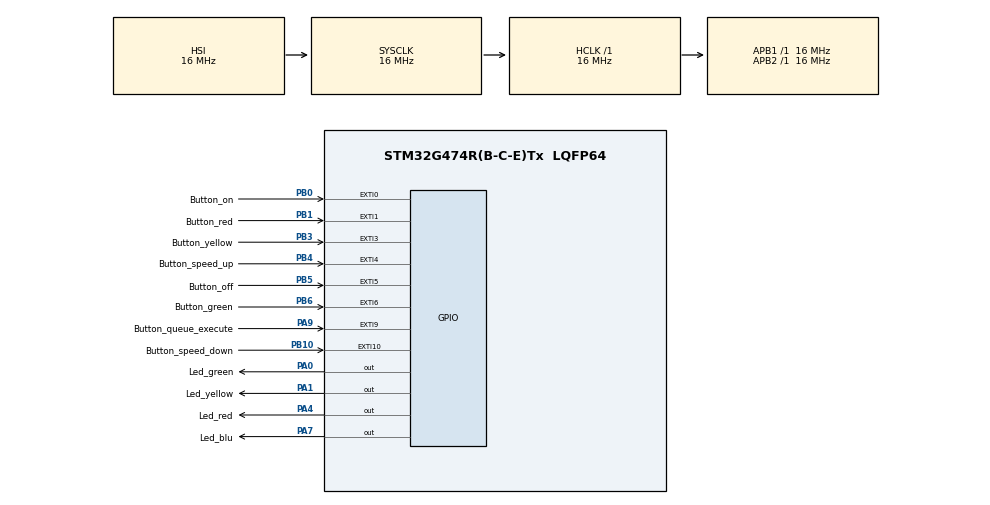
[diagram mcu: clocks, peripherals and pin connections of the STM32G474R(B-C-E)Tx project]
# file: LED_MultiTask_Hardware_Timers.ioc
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Mcu.Family=STM32G4
Mcu.Name=STM32G474R(B-C-E)Tx
Mcu.Package=LQFP64
NVIC.EXTI0_IRQn=true\:0\:0\:false\:false\:true\:true\:true\:true
NVIC.EXTI15_10_IRQn=true\:0\:0\:false\:false\:true\:true\:true\:true
NVIC.EXTI1_IRQn=true\:0\:0\:false\:false\:true\:true\:true\:true
NVIC.EXTI3_IRQn=true\:0\:0\:false\:false\:true\:true\:true\:true
NVIC.EXTI4_IRQn=true\:0\:0\:false\:false\:true\:true\:true\:true
NVIC.EXTI9_5_IRQn=true\:0\:0\:false\:false\:true\:true\:true\:true
NVIC.PriorityGroup=NVIC_PRIORITYGROUP_4
NVIC.TIM1_TRG_COM_TIM17_IRQn=true\:0\:0\:false\:false\:true\:true\:true\:true
NVIC.TIM1_UP_TIM16_IRQn=true\:0\:0\:false\:false\:true\:true\:true\:true
NVIC.TIM6_DAC_IRQn=true\:0\:0\:false\:false\:true\:true\:true\:true
NVIC.TIM7_DAC_IRQn=true\:0\:0\:false\:false\:true\:true\:true\:true
PA0.GPIO_Label=Led_green
PA0.Signal=GPIO_Output
PA1.GPIO_Label=Led_yellow
PA1.Signal=GPIO_Output
PA4.GPIO_Label=Led_red
PA4.Signal=GPIO_Output
PA7.GPIO_Label=Led_blu
PA7.Signal=GPIO_Output
PA9.GPIO_Label=Button_queue_execute
PA9.GPIO_PuPd=GPIO_PULLUP
PA9.Signal=GPXTI9
PB0.GPIO_Label=Button_on
PB0.GPIO_PuPd=GPIO_PULLUP
PB0.Signal=GPXTI0
PB1.GPIO_Label=Button_red
PB1.GPIO_PuPd=GPIO_PULLUP
PB1.Signal=GPXTI1
PB10.GPIO_Label=Button_speed_down
PB10.GPIO_PuPd=GPIO_PULLUP
PB10.Signal=GPXTI10
PB3.GPIO_Label=Button_yellow
PB3.GPIO_PuPd=GPIO_PULLUP
PB3.Signal=GPXTI3
PB4.GPIO_Label=Button_speed_up
PB4.GPIO_PuPd=GPIO_PULLUP
PB4.Signal=GPXTI4
PB5.GPIO_Label=Button_off
PB5.GPIO_PuPd=GPIO_PULLUP
PB5.Signal=GPXTI5
PB6.GPIO_Label=Button_green
PB6.GPIO_PuPd=GPIO_PULLUP
PB6.Signal=GPXTI6
ProjectManager.HeapSize=0x200
ProjectManager.StackSize=0x400
ProjectManager.TargetToolchain=STM32CubeIDE
RCC.AHBFreq_Value=16000000
RCC.APB1Freq_Value=16000000
RCC.APB1TimFreq_Value=16000000
RCC.APB2Freq_Value=16000000
RCC.APB2TimFreq_Value=16000000
RCC.CortexFreq_Value=16000000
RCC.EXTERNAL_CLOCK_VALUE=12288000
RCC.HCLKFreq_Value=16000000
RCC.HSE_VALUE=8000000
RCC.HSI48_VALUE=48000000
RCC.HSI_VALUE=16000000
RCC.LSE_VALUE=32768
RCC.SYSCLKFreq_VALUE=16000000
RCC.USBFreq_Value=64000000
RCC.VCOOutputFreq_Value=128000000
TIM16.PeriodNoDither=999
TIM16.Prescaler=1599
TIM17.AutoReloadPreload=TIM_AUTORELOAD_PRELOAD_ENABLE
TIM17.PeriodNoDither=4999
TIM17.Prescaler=1599
TIM6.PeriodNoDither=4999
TIM6.Prescaler=1599
TIM7.PeriodNoDither=2499
TIM7.Prescaler=1599
VP_SYS_VS_DBSignals.Mode=DisableDeadBatterySignals
VP_TIM16_VS_ClockSourceINT.Mode=Enable_Timer
VP_TIM17_VS_ClockSourceINT.Mode=Enable_Timer
VP_TIM6_VS_ClockSourceINT.Mode=Enable_Timer
VP_TIM7_VS_ClockSourceINT.Mode=Enable_Timer
board=custom

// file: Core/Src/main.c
/* USER CODE BEGIN Header */
/**
 ******************************************************************************
 * @file           : main.c
 * @brief          : Main program body
 ******************************************************************************
 * @attention
 *
 * Copyright (c) 2026 STMicroelectronics.
 * All rights reserved.
 *
 * This software is licensed under terms that can be found in the LICENSE file
 * in the root directory of this software component.
 * If no LICENSE file comes with this software, it is provided AS-IS.
 *
 ******************************************************************************
 */
/* USER CODE END Header */
#include "main.h"
#include "tim.h"
#include "gpio.h"

/* USER CODE BEGIN Includes */
#include "queue.h"
/* USER CODE END Includes */

/* USER CODE BEGIN PD */
// QUEUE_CAPACITY is defined in main.h
/* USER CODE END PD */

void SystemClock_Config(void);

int main(void)
{

  /* MCU Configuration--------------------------------------------------------*/

  /* Reset of all peripherals, Initializes the Flash interface and the Systick. */
  HAL_Init();

  /* Configure the system clock */
  SystemClock_Config();

  /* Initialize all configured peripherals */
  MX_GPIO_Init();
  MX_TIM6_Init();
  MX_TIM7_Init();
  MX_TIM16_Init();
  MX_TIM17_Init();
  /* USER CODE BEGIN 2 */
	extern queue_t led_queue;
	extern uint8_t queue_buffer[];
	queue_init(&led_queue, queue_buffer, sizeof(led_id_t), QUEUE_CAPACITY);

	HAL_TIM_Base_Start_IT(&htim17);
  /* USER CODE END 2 */

  /* Infinite loop */
	while (1) {

	}
}

void SystemClock_Config(void)
{
  RCC_OscInitTypeDef RCC_OscInitStruct = {0};
  RCC_ClkInitTypeDef RCC_ClkInitStruct = {0};

  /** Configure the main internal regulator output voltage
  */
  HAL_PWREx_ControlVoltageScaling(PWR_REGULATOR_VOLTAGE_SCALE1);

  /** Initializes the RCC Oscillators according to the specified parameters
  * in the RCC_OscInitTypeDef structure.
  */
  RCC_OscInitStruct.OscillatorType = RCC_OSCILLATORTYPE_HSI;
  RCC_OscInitStruct.HSIState = RCC_HSI_ON;
  RCC_OscInitStruct.HSICalibrationValue = RCC_HSICALIBRATION_DEFAULT;
  RCC_OscInitStruct.PLL.PLLState = RCC_PLL_NONE;
  if (HAL_RCC_OscConfig(&RCC_OscInitStruct) != HAL_OK)
  {
    Error_Handler();
  }

  /** Initializes the CPU, AHB and APB buses clocks
  */
  RCC_ClkInitStruct.ClockType = RCC_CLOCKTYPE_HCLK|RCC_CLOCKTYPE_SYSCLK
                              |RCC_CLOCKTYPE_PCLK1|RCC_CLOCKTYPE_PCLK2;
  RCC_ClkInitStruct.SYSCLKSource = RCC_SYSCLKSOURCE_HSI;
  RCC_ClkInitStruct.AHBCLKDivider = RCC_SYSCLK_DIV1;
  RCC_ClkInitStruct.APB1CLKDivider = RCC_HCLK_DIV1;
  RCC_ClkInitStruct.APB2CLKDivider = RCC_HCLK_DIV1;

  if (HAL_RCC_ClockConfig(&RCC_ClkInitStruct, FLASH_LATENCY_0) != HAL_OK)
  {
    Error_Handler();
  }
}

void Error_Handler(void)
{
	__disable_irq();
	while (1) {
	}
}
